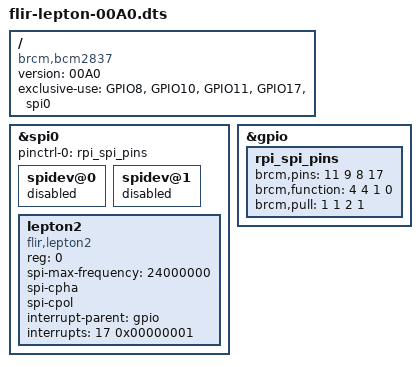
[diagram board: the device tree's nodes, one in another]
/dts-v1/;
/plugin/;

/* Wired up as follows on the Raspberry Pi 3:
	CS -> BCM/GPIO 8 (CEO)
	MOSI -> BCM/GPIO 10 (MOSI)
	MISO -> BCM/GPIO 9 (MISO)
	CLK -> BCM/GPIO 11 (SCLK)
	GND -> GROUND
	VIN -> POWER 3v3
	SDA -> BCM/GPIO 2 (SDA)
	SCL -> BCM/GPIO 3 (SCL)
	VSYNC ->
*/

/ {
	compatible = "brcm,bcm2837", "brcm,bcm2708", "brcm,bcm2709";

	version = "00A0";

	/* state the resources this cape uses */
	exclusive-use =
		/* the pin header uses */
		// SPI0_CS0
		"GPIO8",
		// SPI0_D0 MISO
		"GPIO10",
		// SPI0_SCLK
		"GPIO11",
		// VSYNC
		"GPIO17",


		/* the hardware ip uses */
		"spi0";

	// Disables SPIDEV
	fragment@0 {
		target = <&spi0>;
		__overlay__ {
			status = "okay";

			spidev@0 {
				status = "disabled";
			};

			spidev@1 {
				status = "disabled";
			};
		};
	};

	/* So this fragment is an overlay for the current GPIO settings, which
	   will adjust the default values when applied. Another fragment is
	   needed to apply this overlay */
	fragment@1 {
		// Configuration for the GPIO pin controller
		target = <&gpio>;
		__overlay__ {
			/* default state has all gpios released and mode set to uart1 */
			rpi_spi_pins: rpi_spi_pins {
				brcm,pins = <11 9 8 17>; // clk, d0, cs0, VSYNC
				brcm,function = <4 4 1 0>; // <SPI SPI OUTPUT INPUT>
				brcm,pull = <1 1 2 1>; // 2 = PULLUP, 1  = PULLDOWN
			};
		};
	};

	/* Overlays the GPIO fragment and contains Lepton-specific configuration */
	fragment@2 {
		target = <&spi0>;
		__overlay__ {
			/* AVOIDS DTC WARNING */
			#address-cells = <1>;
			#size-cells = <0>;

			status = "okay";
			pinctrl-names = "default";
			pinctrl-0 = <&rpi_spi_pins>;

			lepton2 {
				#address-cells = <1>;
				#size-cells = <0>;

				compatible = "flir,lepton2";

				/* SPI setup
				 *
				 * lepton SPI mode 3: CPHA = 1, CPOL = 1
				 * p. 50 Lepton with Radiometry Datasheet (500-0736-01-09 rev 110)
				 */
				reg = <0>;
				spi-max-frequency = <24000000>;
				spi-cpha;
				spi-cpol;

				/* VSYNC setup */
				interrupt-parent = <&gpio>;
				interrupts = <17 0x00000001>;
			};
		};
	};
};
